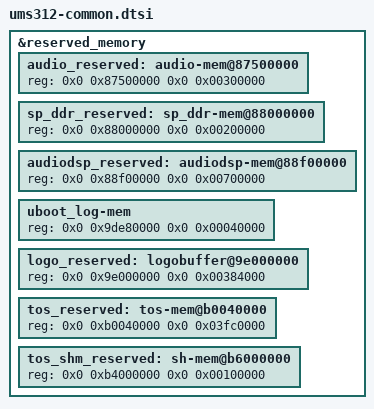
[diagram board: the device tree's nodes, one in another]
// SPDX-License-Identifier: (GPL-2.0+ OR MIT)

#include "modem-4g-common.dtsi"

&reserved_memory {
	audio_reserved: audio-mem@87500000 {
		reg = <0x0 0x87500000 0x0 0x00300000>;
	};

	sp_ddr_reserved: sp_ddr-mem@88000000 {
		reg = <0x0 0x88000000 0x0 0x00200000>;
	};

	audiodsp_reserved: audiodsp-mem@88f00000 {
		reg = <0x0 0x88f00000 0x0 0x00700000>;
	};

	/* The uboot_log_reserved node is added in uboot. base:0x9de8 0000, size:0x40000 */
	uboot_log-mem {
		reg = <0x0 0x9de80000 0x0 0x00040000>;
	};

	logo_reserved: logobuffer@9e000000 {
		reg = <0x0 0x9e000000 0x0 0x00384000>;
	};

	tos_reserved: tos-mem@b0040000 {
		reg = <0x0 0xb0040000 0x0 0x03fc0000>;
	};

	tos_shm_reserved: sh-mem@b6000000 {
		reg = <0x0 0xb4000000 0x0 0x00100000>;
	};
};
